# platform_designer_hps_system_hps_0_hps register map
Vendor: default_vendor.com; File version: 0.0
Registers are 32-bit, read-write, reset 0x0 unless marked. A register's access mark holds for its fields unless they carry their own. Offsets are from the block's base; [hi:lo] are bit positions; {n}, {i} and the like mark numbered series; 'fields as' and 'values as' point back to an identical list.

## usb0 (part 3 of 4) — Registers in the USB OTG Controller Module. Only the Core Global, Power and Clock Gating, Data FIFO Access, and Host Port registers can be accessedin both Host and Device modes. When the USB OTG Controller is operating in one mode, either Device or Host, the application must not access registers from the other mode. If an illegal access occurs, a Mode Mismatch interrupt is generated and reflected in the Core Interrupt register (GINTSTS.ModeMis). When the core switches from one mode to another, the registers in the new mode must be reprogrammed as they would be after a power-on reset. The register address map is fixed and does not depend on the module configuration (for example, how many endpoints are implemented). Host and Device mode registers occupy different addresses.
Base 0xFFB00000
Same registers: usb1 0xFFB40000
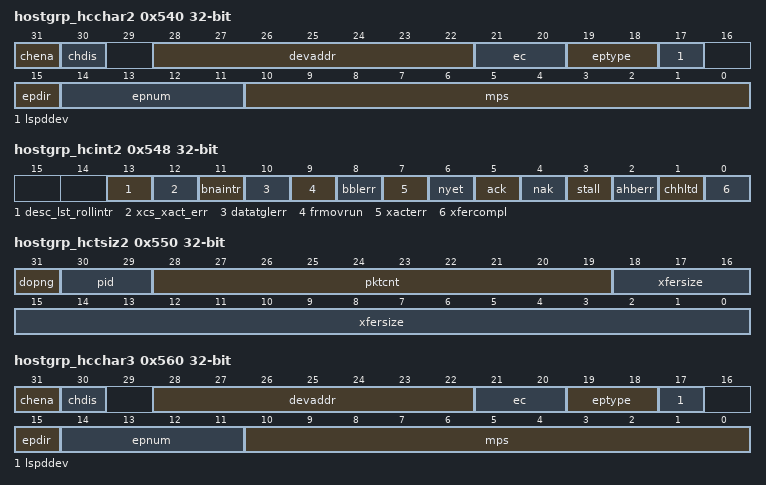
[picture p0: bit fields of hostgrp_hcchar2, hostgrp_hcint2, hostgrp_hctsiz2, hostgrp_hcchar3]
0x540 hostgrp_hcchar2 — Host Channel 2 Characteristics Register
  [31] chena ro — When Scatter/Gather mode is disabled This field is set by the application and cleared by the OTG host. 0: Channel disabled 1: Channel enabled When Scatter/Gather mode is enabled.
    0=inactive; 1=active
  [30] chdis ro — The application sets this bit to stop transmitting/receiving data on a channel, even before the transfer for that channel is complete. The application must wait for the Channel Disabled interrupt before treating the channel as disabled.
    0=inactive; 1=active
  [28:22] devaddr — This field selects the specific device serving as the data source or sink.
  [21:20] ec — When the Split Enable bit of the Host Channel-n Split Control register (HCSPLTn.SpltEna) is reset (0), this field indicates to the host the number of transactions that must be executed per microframe for this periodic endpoint. for non periodic transfers, this field is used only in DMA mode, and specifies the number packets to be fetched for this channel before the internal DMA engine changes arbitration. When HCSPLTn.SpltEna is Set (1), this field indicates the number of immediate retries to be performed for a periodic split transactions on transaction errors. This field must be set to at least 1.
    1=transone; 2=transtwo; 3=transthree
  [19:18] eptype — Indicates the transfer type selected.
    0=ctrl; 1=isoc; 2=bulk; 3=interr
  [17] lspddev — This field is set by the application to indicate that this channel is communicating to a low-speed device. The application must program this bit when a low speed device is connected to the host through an FS HUB. The HS OTG Host core uses this field to drive the XCVR_SELECT signal to 0x3 while communicating to the LS Device through the FS hub. In a peer to peer setup, the HS OTG Host core ignores this bit even if it is set by the application software
    0=disabled; 1=enabled
  [15] epdir — Indicates whether the transaction is IN or OUT.
    0=out; 1=in
  [14:11] epnum — Indicates the endpoint number on the device serving as the data source or sink.
    {v}=endpt{v} (v=0..15)
  [10:0] mps — Indicates the maximum packet size of the associated endpoint.
0x548 hostgrp_hcint2 ro — This register indicates the status of a channel with respect to USB- and AHB-related events. The application must read this register when the Host Channels Interrupt bit of the Core Interrupt register (GINTSTS.HChInt) is set. Before the application can read this register, it must first read the Host All Channels Interrupt (HAINT) register to get the exact channel number for the Host Channel-n Interrupt register. The application must clear the appropriate bit in this register to clear the corresponding bits in the HAINT and GINTSTS registers.
  [13] desc_lst_rollintr — Descriptor rollover interrupt (DESC_LST_ROLLIntr)This bit is valid only when Scatter/Gather DMA mode is enabled. The core sets this bit when the corresponding channel's descriptor list rolls over. for non Scatter/Gather DMA mode, this bit is reserved.
    0=inactive; 1=active
  [12] xcs_xact_err — This bit is valid only when Scatter/Gather DMA mode is enabled. The core sets this bit when 3 consecutive transaction errors occurred on the USB bus. XCS_XACT_ERR will not be generated for Isochronous channels.for non Scatter/Gather DMA mode, this bit is reserved.
    0=inactive; 1=acvtive
  [11] bnaintr — This bit is valid only when Scatter/Gather DMA mode is enabled. The core generates this interrupt when the descriptor accessed is not ready for the Core to process. BNA will not be generated for Isochronous channels. for non Scatter/Gather DMA mode, this bit is reserved.
    0=inactive; 1=active
  [10] datatglerr — This bit can be set only by the core and the application should write 1 to clear it. In Scatter/Gather DMA mode, the interrupt due to this bit is masked in the core.
    0=inactive; 1=active
  [9] frmovrun — In Scatter/Gather DMA mode, the interrupt due to this bit is masked in the core. This bit can be set only by the core and the application should write 1 to clear it.
    0=inactive; 1=active
  [8] bblerr — In Scatter/Gather DMA mode, the interrupt due to this bit is masked in the core..This bit can be set only by the core and the application should write 1 to clear it.
    0=inactive; 1=active
  [7] xacterr — Indicates one of the following errors occurred on the USB.-CRC check failure -Timeout -Bit stuff error -False EOP In Scatter/Gather DMA mode, the interrupt due to this bit is masked in the core. This bit can be set only by the core and the application should write 1 to clear it.
    0=inactive; 1=active
  [6] nyet — In Scatter/Gather DMA mode, the interrupt due to this bit is masked in the core.This bit can be set only by the core and the application should write 1 to clear it.
    0=inactive; 1=active
  [5] ack — In Scatter/Gather DMA mode, the interrupt due to this bit is masked in the core. This bit can be set only by the core and the application should write 1 to clear it.
    0=inactive; 1=active
  [4] nak — In Scatter/Gather DMA mode, the interrupt due to this bit is masked in the core.This bit can be set only by the core and the application should write 1 to clear it.
    0=inactive; 1=active
  [3] stall — In Scatter/Gather DMA mode, the interrupt due to this bit is masked in the core. This bit can be set only by the core and the application should write 1 to clear it.
    0=inactive; 1=active
  [2] ahberr — This is generated only in Internal DMA mode when there is an AHB error during AHB read/write. The application can read the corresponding channel's address register to get the error address.
    0=inactive; 1=active
  [1] chhltd — In non Scatter/Gather DMA mode, it indicates the transfer completed abnormally either because of any USB transaction error or in response to disable request by the application or because of a completed transfer. In Scatter/gather DMA mode, this indicates that transfer completed due to any of the following . EOL being set in descriptor . AHB error . Excessive transaction errors . Babble . Stall
    0=inactive; 1=active
  [0] xfercompl — Transfer completed normally without any errors. This bit can be set only by the core and the application should write 1 to clear it.
    0=inactive; 1=active
0x550 hostgrp_hctsiz2 — Buffer DMA Mode.
  [31] dopng — This bit is used only for OUT transfers.Setting this field to 1 directs the host to do PING protocol. Do not Set this bit for IN transfers. If this bit is set for IN transfers it disables the channel.
    0=noping; 1=ping
  [30:29] pid — The application programs this field with the type of PID to use forthe initial transaction. The host maintains this field for the rest of the transfer.
    0=data0; 1=data2; 2=data1; 3=mdata
  [28:19] pktcnt — This field is programmed by the application with the expected number of packets to be transmitted (OUT) or received (IN). The host decrements this count on every successful transmission or reception of an OUT/IN packet. Once this count reaches zero, the application is interrupted to indicate normal completion. The width of this counter is specified as 10 bits.
  [18:0] xfersize — for an OUT, this field is the number of data bytes the host sends during the transfer. for an IN, this field is the buffer size that the application has Reserved for the transfer. The application is expected to program this field as an integer multiple of the maximum packet size for IN transactions (periodic and non-periodic).The width of this counter is specified as 19 bits.
0x560 hostgrp_hcchar3 — Channel_number: 3.
  [31] chena ro — When Scatter/Gather mode is disabled. This field is set by the application and cleared by the OTG host.
    0=notready; 1=ready
  [30] chdis ro — The application sets this bit to stop transmitting/receiving data on a channel, even before the transfer for that channel is complete. The application must wait for the Channel Disabled interrupt before treating the channel as disabled.
    0=inactive; 1=active
  [28:22] devaddr — This field selects the specific device serving as the data source or sink.
  [21:20] ec — When the Split Enable bit of the Host Channel-n Split Control register (HCSPLTn.SpltEna) is reset (0), this field indicates to the host the number of transactions that must be executed per microframe for this periodic endpoint. for non periodic transfers, this field is used only in DMA mode, and specifies the number packets to be fetched for this channel before the internal DMA engine changes arbitration. When HCSPLTn.SpltEna is Set (1), this field indicates the number of immediate retries to be performed for a periodic split transactions on transaction errors. This field must be Set to at least 1.
    1=transone; 2=transtwo; 3=transthree
  [19:18] eptype — Indicates the transfer type selected.
    0=ctrl; 1=isoc; 2=bulk; 3=interr
  [17] lspddev — This field is Set by the application to indicate that this channel is communicating to a low-speed device. The application must program this bit when a low speed device is connected to the host through an FS HUB. The HS OTG Host core uses this field to drive the XCVR_SELECT signal to 0x3 while communicating to the LS Device through the FS hub. In a peer to peer setup, the HS OTG Host core ignores this bit even if it is set by the application software.
    0=nonlowspeed; 1=lowspeed
  [15] epdir — Indicates whether the transaction is IN or OUT.
    0=outdir; 1=indir
  [14:11] epnum — Indicates the endpoint number on the device serving as the data source or sink.
    {v}=endpt{v} (v=0..15)
  [10:0] mps — Indicates the maximum packet size of the associated endpoint.
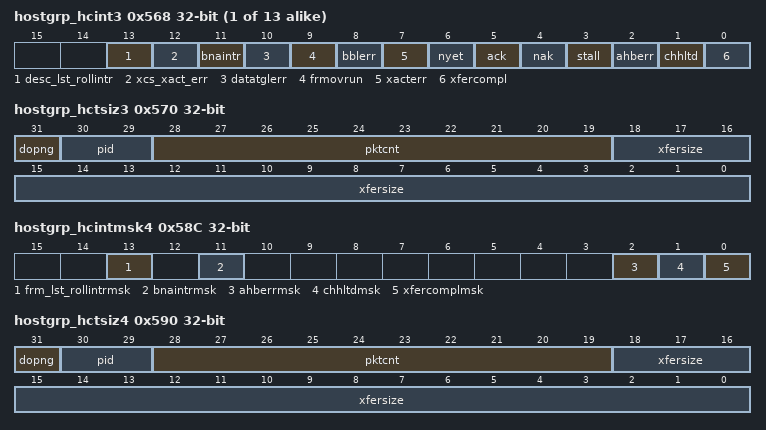
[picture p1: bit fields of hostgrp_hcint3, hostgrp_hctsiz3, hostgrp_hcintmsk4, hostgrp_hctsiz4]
{0x508+0x20*i} hostgrp_hcint{i} ro (i=3..15) — This register indicates the status of a channel with respect to USB- and AHB-related events. The application must read this register when the Host Channels Interrupt bit of the Core Interrupt register (GINTSTS.HChInt) is set. Before the application can read this register, it must first read the Host All Channels Interrupt (HAINT) register to get the exact channel number for the Host Channel-n Interrupt register. The application must clear the appropriate bit in this register to clear the corresponding bits in the HAINT and GINTSTS registers.
  [13] desc_lst_rollintr — Descriptor rollover interrupt (DESC_LST_ROLLIntr)This bit is valid only when Scatter/Gather DMA mode is enabled. The core sets this bit when the corresponding channel's descriptor list rolls over. for non Scatter/Gather DMA mode, this bit is reserved.
    0=inactive; 1=active
  [12] xcs_xact_err — This bit is valid only when Scatter/Gather DMA mode is enabled. The core sets this bit when 3 consecutive transaction errors occurred on the USB bus. XCS_XACT_ERR will not be generated for Isochronous channels.for non Scatter/Gather DMA mode, this bit is reserved.
    0=inactive; 1=acvtive
  [11] bnaintr — This bit is valid only when Scatter/Gather DMA mode is enabled. The core generates this interrupt when the descriptor accessed is not ready for the Core to process. BNA will not be generated for Isochronous channels. for non Scatter/Gather DMA mode, this bit is reserved.
    0=inactive; 1=active
  [10] datatglerr — This bit can be set only by the core and the application should write 1 to clear it. In Scatter/Gather DMA mode, the interrupt due to this bit is masked in the core.
    0=inactive; 1=active
  [9] frmovrun — In Scatter/Gather DMA mode, the interrupt due to this bit is masked in the core. This bit can be set only by the core and the application should write 1 to clear it.
    0=inactive; 1=active
  [8] bblerr — In Scatter/Gather DMA mode, the interrupt due to this bit is masked in the core..This bit can be set only by the core and the application should write 1 to clear it.
    0=inactive; 1=active
  [7] xacterr — Indicates one of the following errors occurred on the USB.-CRC check failure -Timeout -Bit stuff error -False EOP In Scatter/Gather DMA mode, the interrupt due to this bit is masked in the core. This bit can be set only by the core and the application should write 1 to clear it.
    0=inactive; 1=active
  [6] nyet — In Scatter/Gather DMA mode, the interrupt due to this bit is masked in the core.This bit can be set only by the core and the application should write 1 to clear it.
    0=inactive; 1=active
  [5] ack — In Scatter/Gather DMA mode, the interrupt due to this bit is masked in the core. This bit can be set only by the core and the application should write 1 to clear it.
    0=inactive; 1=active
  [4] nak — In Scatter/Gather DMA mode, the interrupt due to this bit is masked in the core.This bit can be set only by the core and the application should write 1 to clear it.
    0=inactive; 1=active
  [3] stall — In Scatter/Gather DMA mode, the interrupt due to this bit is masked in the core. This bit can be set only by the core and the application should write 1 to clear it.
    0=inactive; 1=active
  [2] ahberr — This is generated only in Internal DMA mode when there is an AHB error during AHB read/write. The application can read the corresponding channel's DMA address register to get the error address.
    0=inactive; 1=active
  [1] chhltd — In non Scatter/Gather DMA mode, it indicates the transfer completed abnormally either because of any USB transaction error or in response to disable request by the application or because of a completed transfer. In Scatter/gather DMA mode, this indicates that transfer completed due to any of the following . EOL being set in descriptor . AHB error . Excessive transaction errors . Babble . Stall
    0=inactive; 1=active
  [0] xfercompl — Transfer completed normally without any errors. This bit can be set only by the core and the application should write 1 to clear it.
    0=inactive; 1=active
0x570 hostgrp_hctsiz3 — Buffer DMA Mode
  fields as hostgrp_hctsiz2
0x580 hostgrp_hcchar4 — These registers are present only in case of Scatter/Gather DMA. These registers are implemented in RAM instead of flop-based implementation. Holds the current buffer address. This register is updated as and when the data transfer for the corresponding end point is in progress. This register is present only in Scatter/Gather DMA mode. Otherwise this field is reserved.
  [31:0] hcdmab4
0x58C hostgrp_hcintmsk4 — This register reflects the mask for Channel 4 interrupt status bits.
  [all] fields
    0=mask; 1=nomask
  [13] frm_lst_rollintrmsk — This bit is valid only when Scatter/Gather DMA mode is enabled.
  [11] bnaintrmsk — This bit is valid only when Scatter/Gather DMA mode is enabled.
  [2] ahberrmsk — In scatter/gather DMA mode for host, interrupts will not be generated due to the corresponding bits set in HCINTn.
  [1] chhltdmsk — Channel Halted.
  [0] xfercomplmsk — Transfer complete.
0x590 hostgrp_hctsiz4 — Buffer DMA Mode Channel 4
  fields as hostgrp_hctsiz2
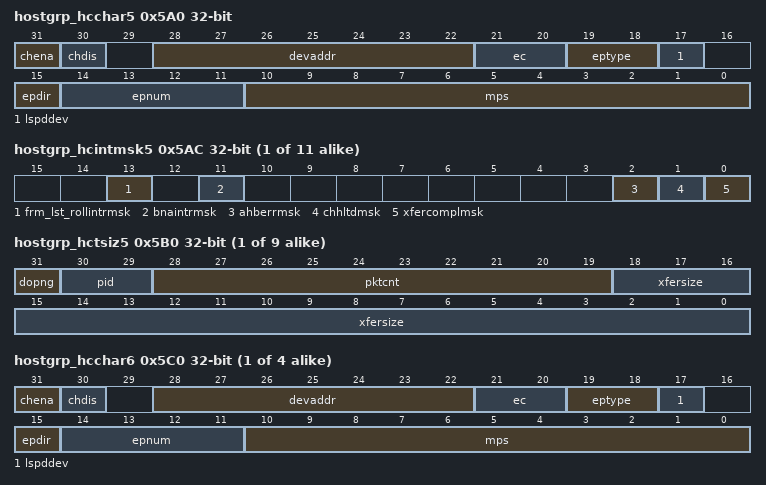
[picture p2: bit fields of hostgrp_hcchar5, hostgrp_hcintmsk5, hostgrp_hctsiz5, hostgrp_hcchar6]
0x5A0 hostgrp_hcchar5 — Channel_number: 5.
  [31] chena ro — When Scatter/Gather mode is disabled. This field is set by the application and cleared by the OTG host.
    0=notready; 1=ready
  [30] chdis ro — The application sets this bit to stop transmitting/receiving data on a channel, even before the transfer for that channel is complete. The application must wait for the Channel Disabled interrupt before treating the channel as disabled.
    0=inactive; 1=active
  [28:22] devaddr — This field selects the specific device serving as the data source or sink.
  [21:20] ec — When the Split Enable bit of the Host Channel-n Split Control register (HCSPLTn.SpltEna) is reset (0), this field indicates to the host the number of transactions that must be executed per microframe for this periodic endpoint. for non periodic transfers, this field is used only in DMA mode, and specifies the number packets to be fetched for this channel before the internal DMA engine changes arbitration. 0x0: Reserved This field yields undefined results. 0x1: transaction 0x2: 2 transactions to be issued for this endpoint permicroframe 0x3: 3 transactions to be issued for this endpoint permicroframeWhen HCSPLTn.SpltEna is Set (1), this field indicates thenumber of immediate retries to be performed for a periodic splittransactions on transaction errors. This field must be Set to atleast 1.
    1=transone; 2=transtwo; 3=transthree
  [19:18] eptype — Indicates the transfer type selected.
    0=ctrl; 1=isoc; 2=bulk; 3=interr
  [17] lspddev — This field is Set by the application to indicate that this channel is communicating to a low-speed device. The application must program this bit when a low speed device is connected to the host through an FS HUB. The HS OTG Host core uses this field to drive the XCVR_SELECT signal to 0x3 while communicating to the LS Device through the FS hub. In a peer to peer setup, the HS OTG Host core ignores this bit even if it is set by the application software.
    0=nonlowspeed; 1=lowspeed
  [15] epdir — Indicates whether the transaction is IN or OUT.
    0=outdir; 1=indir
  [14:11] epnum — Indicates the endpoint number on the device serving as the data source or sink.
    {v}=endpt{v} (v=0..15)
  [10:0] mps — Indicates the maximum packet size of the associated endpoint.
{0x50C+0x20*i} hostgrp_hcintmsk{i} (i=5..15) — This register reflects the mask for each channel status described in the previous section.
  fields as hostgrp_hcintmsk4
{0x510+0x20*i} hostgrp_hctsiz{i} (i=5..13) — Buffer DMA Mode
  fields as hostgrp_hctsiz2
{0x500+0x20*i} hostgrp_hcchar{i} (i=6..9) — Host Channel {i} Characteristics Register
  fields as hostgrp_hcchar2
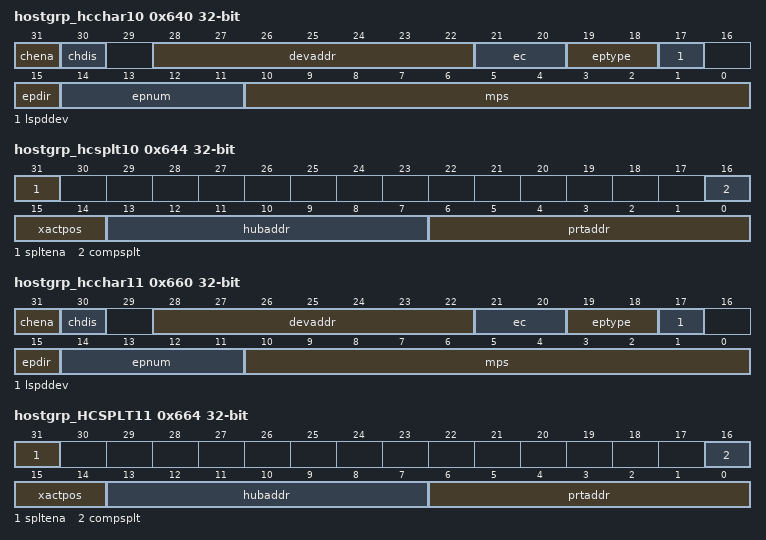
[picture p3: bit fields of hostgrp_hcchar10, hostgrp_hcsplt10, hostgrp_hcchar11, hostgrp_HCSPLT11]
0x640 hostgrp_hcchar10 — Host Channel 1 Characteristics Register
  fields as hostgrp_hcchar2
0x644 hostgrp_hcsplt10 — Channel_number 1
  [31] spltena — The application sets this field to indicate that this channel is enabled to perform split transactions.
    0=disabled; 1=enabled
  [16] compsplt — The application sets this field to request the OTG host to perform a complete split transaction.
    0=nosplit; 1=split
  [15:14] xactpos — This field is used to determine whether to send all, first, middle, or last payloads with each OUT transaction.
    0=middle; 1=end; 2=begin; 3=all
  [13:7] hubaddr — This field holds the device address of the transaction translator's hub.
  [6:0] prtaddr — This field is the port number of the recipient transactiontranslator.
0x660 hostgrp_hcchar11 — Host Channel 11 Characteristics Register
  fields as hostgrp_hcchar2
0x664 hostgrp_HCSPLT11 — Channel number 11.
  fields as hostgrp_hcsplt10
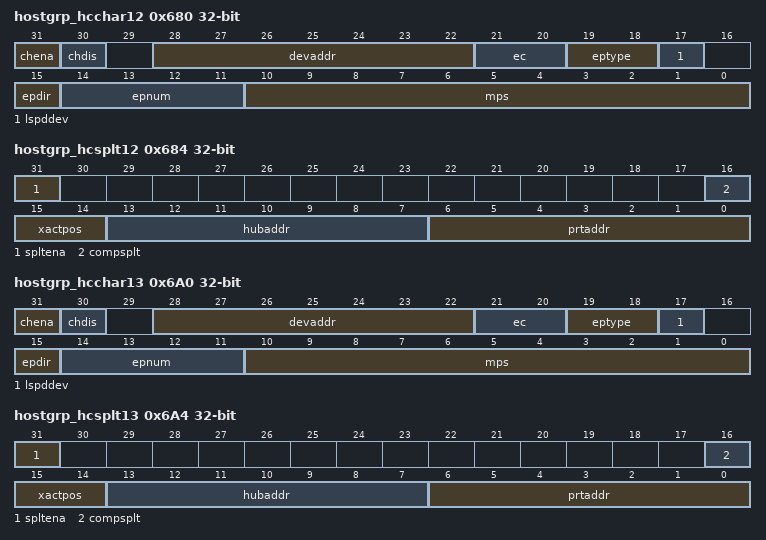
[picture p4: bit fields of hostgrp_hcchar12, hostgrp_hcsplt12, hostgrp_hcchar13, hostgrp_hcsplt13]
0x680 hostgrp_hcchar12 — Host Channel 1 Characteristics Register
  fields as hostgrp_hcchar2
0x684 hostgrp_hcsplt12 — Channel_number 1
  fields as hostgrp_hcsplt10
0x6A0 hostgrp_hcchar13 — Host Channel 13 Characteristics Register
  fields as hostgrp_hcchar2
0x6A4 hostgrp_hcsplt13 — Channel_number 13.
  fields as hostgrp_hcsplt10
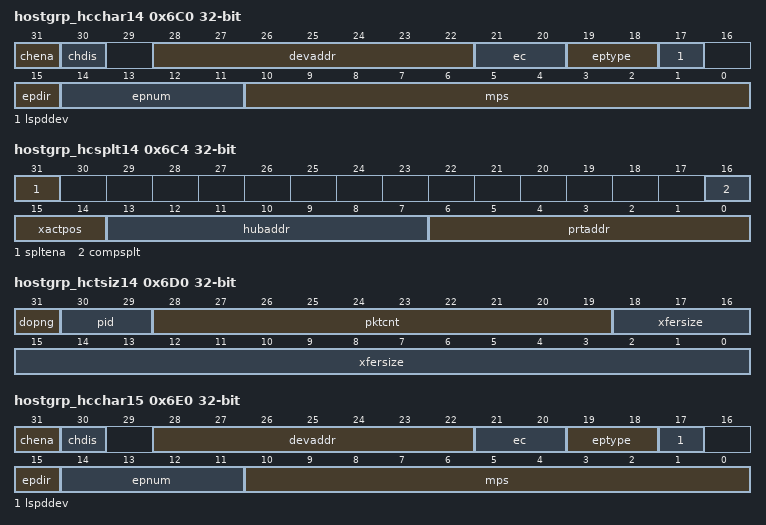
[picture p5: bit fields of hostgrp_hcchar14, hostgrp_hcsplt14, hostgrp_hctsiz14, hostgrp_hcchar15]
0x6C0 hostgrp_hcchar14 — Host Channel 1 Characteristics Register
  fields as hostgrp_hcchar2
0x6C4 hostgrp_hcsplt14 — Channel_number 14
  fields as hostgrp_hcsplt10
0x6D0 hostgrp_hctsiz14
  [31] dopng — This bit is used only for OUT transfers.Setting this field to 1 directs the host to do PING protocol. Do not Set this bit for IN transfers. If this bit is set for IN transfers it disables the channel.
    0=noping; 1=ping
  [30:29] pid — The application programs this field with the type of PID to use forthe initial transaction. The host maintains this field for the rest of the transfer.
    0=data0; 1=data2; 2=data1; 3=mdata
  [28:19] pktcnt — This field is programmed by the application with the expected number of packets to be transmitted (OUT) or received (IN). The host decrements this count on every successful transmission or reception of an OUT/IN packet. Once this count reaches zero, the application is interrupted to indicate normal completion. The width of this counter is specified as 10 bits.
  [18:0] xfersize — for an OUT, this field is the number of data bytes the host sends during the transfer. for an IN, this field is the buffer size that the application has Reserved for the transfer. The application is expected to program this field as an integer multiple of the maximum packet size for IN transactions (periodic and non-periodic). The width of this counter is specified as 19 bits.
0x6E0 hostgrp_hcchar15 — Host Channel 15 Characteristics Register
  [31] chena ro — When Scatter/Gather mode is disabled This field is set by the application and cleared by the OTG host. 0: Channel disabled 1: Channel enabled When Scatter/Gather mode is enabled.
    0=inactive; 1=active
  [30] chdis ro — The application sets this bit to stop transmitting/receiving data on a channel, even before the transfer for that channel is complete. The application must wait for the Channel Disabled interrupt before treating the channel as disabled.
    0=inactive; 1=active
  [28:22] devaddr — This field selects the specific device serving as the data source or sink.
  [21:20] ec — When the Split Enable bit of the Host Channel-n Split Control register (HCSPLTn.SpltEna) is reset (0), this field indicates to the host the number of transactions that must be executed per microframe for this periodic endpoint. for non periodic transfers, this field is used only in DMA mode, and specifies the number packets to be fetched for this channel before the internal DMA engine changes arbitration. When HCSPLTn.SpltEna is Set (1), this field indicates the number of immediate retries to be performed for a periodic split transactions on transaction errors. This field must be set to at least 1.
    1=transone; 2=transtwo; 3=transthree
  [19:18] eptype — Indicates the transfer type selected.
    0=ctrl; 1=isoc; 2=bulk; 3=interr
  [17] lspddev — This field is set by the application to indicate that this channel is communicating to a low-speed device. The application must program this bit when a low speed device is connected to the host through an FS HUB. The HS OTG Host core uses this field to drive the XCVR_SELECT signal to 2'b11 while communicating to the LS Device through the FS hub. In a peer to peer setup, the HS OTG Host core ignores this bit even if it is set by the application software
    0=disabled; 1=enabled
  [15] epdir — Indicates whether the transaction is IN or OUT.
    0=out; 1=in
  [14:11] epnum — Indicates the endpoint number on the device serving as the data source or sink.
    {v}=endpt{v} (v=0..15)
  [10:0] mps — Indicates the maximum packet size of the associated endpoint.
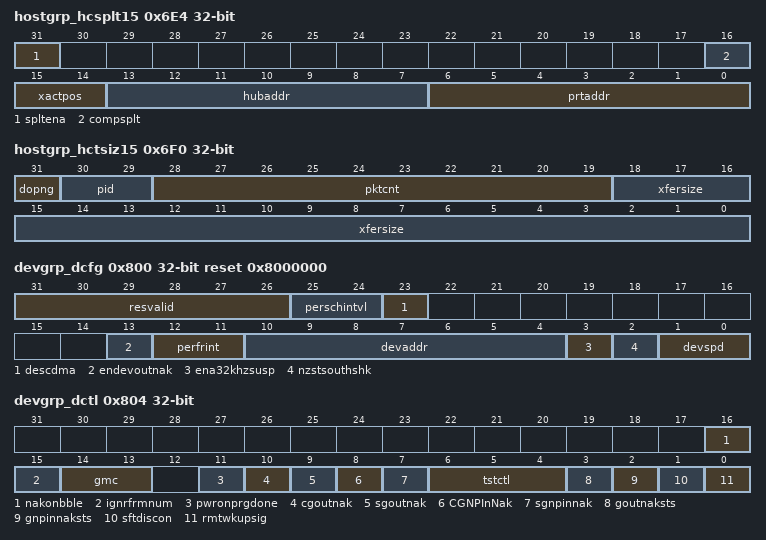
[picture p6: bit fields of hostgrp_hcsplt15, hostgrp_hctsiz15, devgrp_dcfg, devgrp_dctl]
0x6E4 hostgrp_hcsplt15 — Channel_number 15.
  fields as hostgrp_hcsplt10
0x6F0 hostgrp_hctsiz15
  fields as hostgrp_hctsiz2
0x800 devgrp_dcfg reset 0x8000000 — This register configures the core in Device mode after power-on or after certain control commands or enumeration. Do not make changes to this register after initial programming.
  [31:26] resvalid — This field is effective only when DCFG.Ena32KHzSusp is set. It will control the resume period when the core resumes from suspend. The core counts for ResValid number of clock cycles to detect a valid resume when this is set
  [25:24] perschintvl — PerSchIntvl must be programmed only for Scatter/Gather DMAmode. Description: This field specifies the amount of time the Internal DMA engine must allocate for fetching periodic IN endpoint data. Based on the number of periodic endpoints, this value must be specified as 25,50 or 75% of (micro)frame. When any periodic endpoints are active, the internal DMA engine allocates the specified amount of time in fetching periodic IN endpoint data . When no periodic endpoints are active, Then the internal DMA engine services non-periodic endpoints, ignoring this field. After the specified time within a (micro)frame, the DMA switches to fetching for non-periodic endpoints. 2'b00: 25% of (micro)frame. 2'b01: 50% of (micro)frame. 2'b10: 75% of (micro)frame. 2'b11: Reserved.Reset: 2'b00Access: read-write
    0=mf25; 1=mf50; 2=mf75
  [23] descdma — When the Scatter/Gather DMA option selected during configuration of the RTL, the application can Set this bit during initialization to enable the Scatter/Gather DMA operation. This bit must be modified only once after a reset.The following combinations are available for programming: GAHBCFG.DMAEn=0,DCFG.DescDMA=0 => Slave mode GAHBCFG.DMAEn=0,DCFG.DescDMA=1 => Invalid GAHBCFG.DMAEn=1,DCFG.DescDMA=0 => Buffered DMA mode GAHBCFG.DMAEn=1,DCFG.DescDMA=1 => Scatter/Gather DMA mode
    0=disabled; 1=enabled
  [13] endevoutnak — This bit enables setting NAK for Bulk OUT endpoints after the transfer is completed for Device mode Descriptor DMA It is one time programmable after reset like any other DCFG register bits.
    0=disabled; 1=enabled
  [12:11] perfrint — Indicates the time within a (micro)frame at which the application must be notified using the End Of Periodic Frame Interrupt. This can be used to determine If all the isochronous traffic for that (micro)frame is complete. 0x0: 80% of the (micro)frame interval 0x1: 85% 0x2: 90% 0x3: 95%
    0=eopf80; 1=eopf85; 2=eopf90; 3=eopf95
  [10:4] devaddr — The application must program this field after every SetAddress control command.
  [3] ena32khzsusp — When the USB 1.1 Full-Speed Serial Transceiver Interface is chosen and this bit is set, the core expects the 48-MHz PHY clock to be switched to 32 KHz during a suspend. This bit can only be set if USB 1.1 Full-Speed Serial Transceiver Interface has been selected. If USB 1.1 Full-Speed Serial Transceiver Interface has not been selected, this bit must be zero.
    0=disabled; 1=enabled
  [2] nzstsouthshk — The application can use this field to select the handshake the core sends on receiving a nonzero-length data packet during the OUT transaction of a control transfer's Status stage. 1: Send a STALL handshake on a nonzero-length statusOUT transaction and do not send the received OUT packet tothe application. 0: Send the received OUT packet to the application (zerolengthor nonzero-length) and send a handshake based onthe NAK and STALL bits for the endpoint in the DeviceEndpoint Control register.
    0=sendout; 1=sendstall
  [1:0] devspd — Indicates the speed at which the application requires the core to enumerate, or the maximum speed the application can support. However, the actual bus speed is determined only after the chirp sequence is completed, and is based on the speed of the USB host to which the core is connected.
    0=usbhs20; 1=usbfs20; 2=usbls116; 3=usbls1148
0x804 devgrp_dctl
  [16] nakonbble — Set NAK automatically on babble (NakOnBble). The core sets NAK automatically for the endpoint on which babble is received.
    0=disabled; 1=enabled
  [15] ignrfrmnum — Do NOT program IgnrFrmNum bit to 1'b1 when the core is operating in threshold mode. When Scatter/Gather DMA mode is enabled this feature is not applicable to High Speed, High bandwidth transfers. When this bit is enabled, there must be only one packet per descriptor. In Scatter/Gather DMA mode, if this bit is enabled, the packets are not flushed when a ISOC IN token is received for an elapsed frame. When Scatter/Gather DMA mode is disabled, this field is used by the application to enable periodic transfer interrupt. The application can program periodic endpoint transfers for multiple (micro)frames. 0: periodic transfer interrupt feature is disabled, application needs to program transfers for periodic endpoints every (micro)frame 1: periodic transfer interrupt feature is enabled, application can program transfers for multiple (micro)frames for periodic endpoints. In non Scatter/Gather DMA mode the application will receive transfer complete interrupt after transfers for multiple (micro)frames are completed.
    0=disabled; 1=enabled
  [14:13] gmc — GMC must be programmed only once after initialization.Applicable only for Scatter/Gather DMA mode. This indicates the number of packets to be serviced for that end point before moving to the next end point. It is only for non-periodic end points. When Scatter/Gather DMA mode is disabled, this field isreserved. and reads 0.
    0=notvalid; 1=onepacket; 2=twopacket; 3=threepacket
  [11] pwronprgdone — The application uses this bit to indicate that registerprogramming is completed after a wake-up from Power Downmode.
    0=notdone; 1=done
  [10] cgoutnak wo — A write to this field clears the Global OUT NAK.
    0=disabled; 1=enabled
  [9] sgoutnak wo — A write to this field sets the Global OUT NAK.The application uses this bit to send a NAK handshake on all OUT endpoints. The application must Set the this bit only after making sure that the Global OUT NAK Effective bit in the Core Interrupt Register GINTSTS.GOUTNakEff) is cleared.
    0=disabled; 1=enabled
  [8] CGNPInNak wo — A write to this field clears the Global Non-periodic IN NAK.
    0=disable; 1=enable
  [7] sgnpinnak wo — A write to this field sets the Global Non-periodic IN NAK. The application uses this bit to send a NAK handshake on all nonperiodic IN endpoints. The core can also Set this bit when a timeout condition is detected on a non-periodic endpoint in shared FIFO operation. The application must Set this bit only after making sure that the Global IN NAK Effective bit in the Core Interrupt Register (GINTSTS.GINNakEff) is cleared
    0=disabled; 1=enabled
  [6:4] tstctl — Others: Reserved.
    0=disabled; 1=testj; 2=testk; 3=testsn; 4=testpm; 5=testfe
  [3] goutnaksts ro — Reports NAK status. All isochronous OUT packets aredropped.
    0=inactive; 1=active
  [2] gnpinnaksts ro — Defines IN NAK conditions.
    0=inactive; 1=active
  [1] sftdiscon — The application uses this bit to signal the otg core to do a soft disconnect. As long as this bit is Set, the host does not see that the device is connected, and the device does not receive signals on the USB. The core stays in the disconnected state until the application clears this bit. There is a minimum duration for which the core must keep this bit set. When this bit is cleared after a soft disconnect, the core drives the phy_opmode_o signal on the ULPI, which generates a device connect event to the USB host. When the device is reconnected, the USB host restarts device enumeration.;
    0=nodisconnect; 1=disconnect
  [0] rmtwkupsig — When the application sets this bit, the core initiates remote signaling to wake up the USB host. The application must Set this bit to instruct the core to exit the Suspend state. As specified in the USB 2.0 specification, the application must clear this bit 115 ms after setting it. Remote Wakeup Signaling (RmtWkUpSig) When LPM is enabled, In L1 state the behavior of this bit is as follows: When the application sets this bit, the core initiates L1 remote signaling to wake up the USB host. The application must set this bit to instruct the core to exit the Sleep state. As specified in the LPM specification, the hardware will automatically clear this bit after a time of 50us (TL1DevDrvResume) after set by application. Application should not set this bit when GLPMCFG bRemoteWake from the previous LPM transaction was zero.
    0=noexit; 1=exit
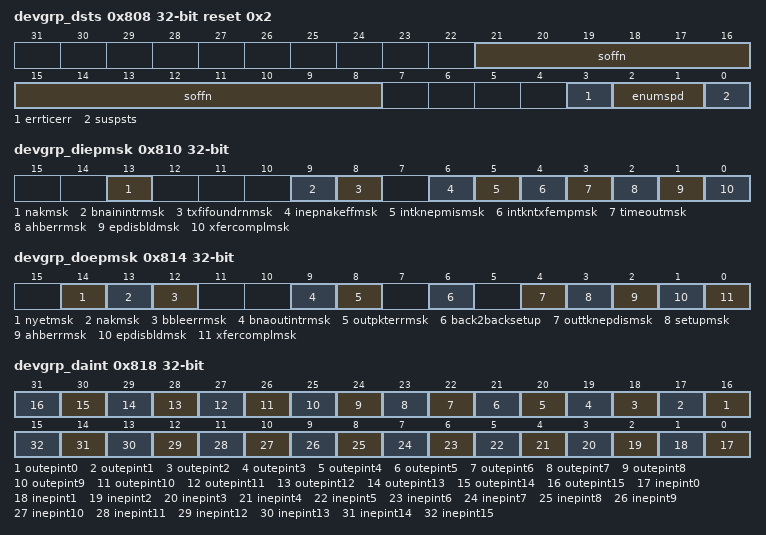
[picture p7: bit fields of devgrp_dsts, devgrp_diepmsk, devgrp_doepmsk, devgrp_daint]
0x808 devgrp_dsts ro reset 0x2 — This register indicates the status of the core with respect to USB-related events. It must be read on interrupts from Device All Interrupts (DAINT) register.
  [21:8] soffn — When the core is operating at high speed, this field contains a microframe number. When the core is operating at full or low speed, this field contains a Frame number.
  [3] errticerr — The core sets this bit to report any erratic errors (phy_rxvalid_i/phy_rxvldh_i or phy_rxactive_i is asserted for at least 2 ms, due to PHY error) seen on the UTMI+ . Due to erratic errors, the otg core goes into Suspended state and an interrupt is generated to the application with Early Suspend bit of the Core Interrupt register (GINTSTS.ErlySusp). If the early suspend is asserted due to an erratic error, the application can only perform a soft disconnect recover.
    0=inactive; 1=active
  [2:1] enumspd — Indicates the speed at which the otg core has come up after speed detection through a chirp sequence.
    0=hs3060; 1=fs3060; 2=ls6; 3=fs48
  [0] suspsts — In Device mode, this bit is Set as long as a Suspend condition is detected on the USB. The core enters the Suspended state when there is no activity on the phy_line_state_i signal for an extended period of time. The core comes out of the suspend: -When there is any activity on the phy_line_state_i signal -When the application writes to the Remote Wakeup Signaling bit in the Device Control register (DCTL.RmtWkUpSig).
    0=inactive; 1=active
0x810 devgrp_diepmsk — This register works with each of the Device IN Endpoint Interrupt (DIEPINTn) registers for all endpoints to generate an interrupt per IN endpoint. The IN endpoint interrupt for a specific status in the DIEPINTn register can be masked by writing to the corresponding bit in this register. Status bits are masked by default.
  [all] fields
    0=mask; 1=nomask
  [13] nakmsk
  [9] bnainintrmsk
  [8] txfifoundrnmsk
  [6] inepnakeffmsk
  [5] intknepmismsk
  [4] intkntxfempmsk
  [3] timeoutmsk — Non-isochronous endpoints
  [2] ahberrmsk
  [1] epdisbldmsk
  [0] xfercomplmsk
0x814 devgrp_doepmsk — This register works with each of the Device OUT Endpoint Interrupt (DOEPINTn) registers for all endpoints to generate an interrupt per OUT endpoint. The OUT endpoint interrupt for a specific status in the DOEPINTn register can be masked by writing into the corresponding bit in this register. Status bits are masked by default
  [all] fields
    0=mask; 1=nomask
  [14] nyetmsk
  [13] nakmsk
  [12] bbleerrmsk
  [9] bnaoutintrmsk
  [8] outpkterrmsk
  [6] back2backsetup — Applies to control OUT endpoints only.
  [4] outtknepdismsk — Applies to control OUT endpoints only.
  [3] setupmsk — Applies to control endpoints only.
  [2] ahberrmsk
  [1] epdisbldmsk
  [0] xfercomplmsk
0x818 devgrp_daint ro — When a significant event occurs on an endpoint, a Device All Endpoints Interrupt register interrupts the application using the Device OUT Endpoints Interrupt bit or Device IN Endpoints Interrupt bit of the Core Interrupt register (GINTSTS.OEPInt or GINTSTS.IEPInt, respectively). This is shown in Figure 5-2. There is one interrupt bit per endpoint, up to a maximum of 16 bits for OUT endpoints and 16 bits for IN endpoints. for a bidirectional endpoint, the corresponding IN and OUT interrupt bits are used. Bits in this register are set and cleared when the application sets and clears bits in the corresponding Device Endpoint-n Interrupt register (DIEPINTn/DOEPINTn).
  [all] fields
    0=inactive; 1=active
  [n+16] outepint{n} (n=0..15)
  [n] inepint{n} (n=0..15)
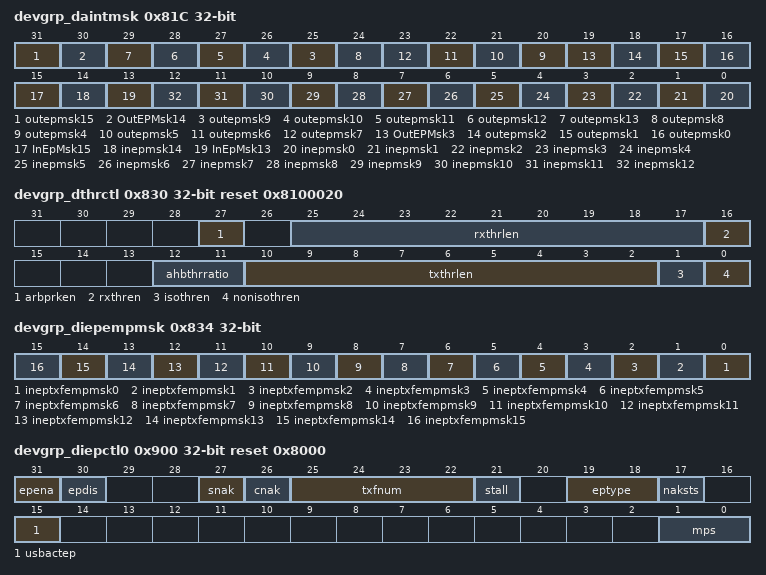
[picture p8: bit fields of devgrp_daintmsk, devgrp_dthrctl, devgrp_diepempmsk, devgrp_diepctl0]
0x81C devgrp_daintmsk — The Device Endpoint Interrupt Mask register works with the Device Endpoint Interrupt register to interrupt the application when an event occurs on a device endpoint. However, the Device All Endpoints Interrupt (DAINT) register bit corresponding to that interrupt is still set.
  [31] outepmsk15
    1=nomask; 0=mask
  [30] OutEPMsk14
    1=nomask; 0=mask
  [n+16] outepmsk{n} (n=9..13)
    1=nomask; 0=mask
  [24] outepmsk8 — OUT Endpoint 8 Interrupt mask Bit
    1=nomask; 0=mask
  [n+16] outepmsk{n} (n=4..7)
    1=nomask; 0=mask
  [19] OutEPMsk3
    1=nomask; 0=mask
  [18] outepmsk2
    1=nomask; 0=mask
  [17] outepmsk1
    1=nomask; 0=mask
  [16] outepmsk0
    1=nomask; 0=mask
  [15] InEpMsk15 — IN Endpoint 15 Interrupt mask Bit
    0=inactive; 1=active
  [14] inepmsk14
    1=nomask; 0=mask
  [13] InEpMsk13
    1=nomask; 0=mask
  [n] inepmsk{n} (n=0..12)
    1=nomask; 0=mask
0x828 devgrp_dvbusdis reset 0x17D7 — This register specifies the VBUS discharge time after VBUS pulsing during SRP.
  [15:0] dvbusdis — This value equals: VBUS discharge time in PHY clocks/1,024 The value you use depends whether the PHY is operating at 30 MHz (16-bit data width) or 60 MHz (8-bit data width). Depending on your VBUS load, this value can need adjustment.
0x82C devgrp_dvbuspulse reset 0x5B8 — This register specifies the VBUS pulsing time during SRP.
  [11:0] dvbuspulse — Specifies the VBUS pulsing time during SRP. This value equals: VBUS pulsing time in PHY clocks/1,024 The value you use depends whether the PHY is operating at 30MHz (16-bit data width) or 60 MHz (8-bit data width).
0x830 devgrp_dthrctl reset 0x8100020 — Thresholding is not supported in Slave mode and so this register must not be programmed in Slave mode. for threshold support, the AHB must be run at 60 MHz or higher.
  [27] arbprken — This bit controls internal DMA arbiter parking for IN endpoints. When thresholding is enabled and this bit is Set to one, Then the arbiter parks on the IN endpoint for which there is a token received on the USB. This is done to avoid getting into underrun conditions. By Default the parking is enabled.
    0=disabled; 1=enabled
  [25:17] rxthrlen — This field specifies Receive thresholding size in DWORDS.This field also specifies the amount of data received on the USB before the core can start transmitting on the AHB. The threshold length has to be at least eight DWORDS. The recommended value for ThrLen is to be the same as the programmed AHB Burst Length (GAHBCFG.HBstLen).
  [16] rxthren — When this bit is Set, the core enables thresholding in the receive direction.
    0=disabled; 1=enabled
  [12:11] ahbthrratio — These bits define the ratio between the AHB threshold and the MAC threshold for the transmit path only. The AHB threshold always remains less than or equal to the USB threshold, because this does not increase overhead. Both the AHB and the MAC threshold must be DWORD-aligned. The application needs to program TxThrLen and the AHBThrRatio to make the AHB Threshold value DWORD aligned. If the AHB threshold value is not DWORD aligned, the core might not behave correctly. When programming the TxThrLen and AHBThrRatio, the application must ensure that the minimum AHB threshold value does not go below 8 DWORDS to meet the USB turnaround time requirements.
    0=threszero; 1=thresone; 2=threstwo; 3=thresthree
  [10:2] txthrlen — This field specifies Transmit thresholding size in DWORDS. This also forms the MAC threshold and specifies the amount of data in bytes to be in the corresponding endpoint transmit FIFO, before the core can start transmit on the USB. The threshold length has to be at least eight DWORDS when the value of AHBThrRatio is 0. In case the AHBThrRatio is non zero the application needs to ensure that the AHB Threshold value does not go below the recommended eight DWORD. This field controls both isochronous and non-isochronous IN endpoint thresholds. The recommended value for ThrLen is to be the same as the programmed AHB Burst Length (GAHBCFG.HBstLen).
  [1] isothren — When this bit is Set, the core enables thresholding for isochronous IN endpoints.
    0=disabled; 1=enabled
  [0] nonisothren — When this bit is Set, the core enables thresholding for Non Isochronous IN endpoints.
    0=disabled; 1=enabled
0x834 devgrp_diepempmsk — This register is used to control the IN endpoint FIFO empty interrupt generation (DIEPINTn.TxfEmp).
  [all] fields
    0=mask; 1=nomask
  [n] ineptxfempmsk{n} (n=0..15) — This bit acts as mask bits for DIEPINT{n}.
0x900 devgrp_diepctl0 reset 0x8000 — This register covers Device Control IN Endpoint 0.
  [31] epena ro — When Scatter/Gather DMA mode is enabled, for IN endpoints this bit indicates that the descriptor structure and data buffer with data ready to transmit is setup. When Scatter/Gather DMA mode is disabled such as in bufferpointer based DMA mode this bit indicates that data is ready to be transmitted on the endpoint. The core clears this bit before setting the following interrupts on this endpoint: -Endpoint Disabled -Transfer Completed
    0=inactive; 1=active
  [30] epdis ro — The application sets this bit to stop transmitting data on an endpoint, even before the transfer for that endpoint is complete. The application must wait for the Endpoint Disabled interrupt before treating the endpoint as disabled. The core clears this bit before setting the Endpoint Disabled Interrupt. The application must Set this bit only If Endpoint Enable is already Set for this endpoint.
    0=inactive; 1=active
  [27] snak wo — A write to this bit sets the NAK bit for the endpoint. Using this bit, the application can control the transmission of NAK handshakes on an endpoint. The core can also Set this bit for an endpoint after a SETUP packet is received on that endpoint.
    0=noset; 1=set
  [26] cnak wo — A write to this bit clears the NAK bit for the endpoint.
    0=noclear; 1=clear
  [25:22] txfnum — for Shared FIFO operation, this value is always Set to 0, indicating that control IN endpoint 0 data is always written in the Non-Periodic Transmit FIFO. for Dedicated FIFO operation, this value is Set to the FIFO number that is assigned to IN Endpoint 0.
  [21] stall ro — The application can only Set this bit, and the core clears it, when a SETUP token is received for this endpoint. If a NAK bit, Global Nonperiodic IN NAK, or Global OUT NAK is Set along with this bit, the STALL bit takes priority.
    0=inactive; 1=active
  [19:18] eptype ro — Hardcoded to 00 for control.
    0=active
  [17] naksts ro — When this bit is Set, either by the application or core, the core stops transmitting data, even If there is data available in the TxFIFO. Irrespective of this bit's setting, the core always responds to SETUP data packets with an ACK handshake.
    0=inactive; 1=active
  [15] usbactep ro — This bit is always SET to 1, indicating that control endpoint 0 is always active in all configurations and interfaces.
    1=active0
  [1:0] mps — Applies to IN and OUT endpoints.The application must program this field with the maximum packet size for the current logical endpoint.
    0=bytes64; 1=bytes32; 2=bytes16; 3=bytes8
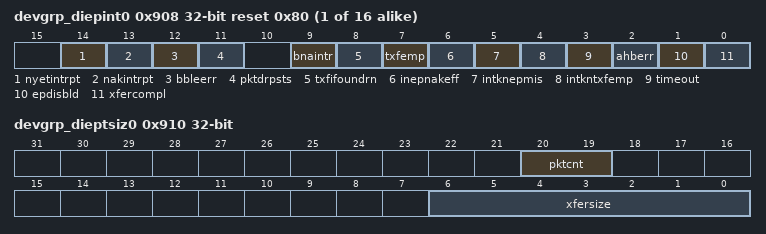
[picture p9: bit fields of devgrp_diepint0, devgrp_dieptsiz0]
{0x908+0x20*i} devgrp_diepint{i} ro reset 0x80 (i=0..15) — This register indicates the status of an endpoint with respect to USB- and AHB-related events. The application must read this register when the OUT Endpoints Interrupt bit or IN Endpoints Interrupt bit of the Core Interrupt register (GINTSTS.OEPInt or GINTSTS.IEPInt, respectively) is set. Before the application can read this register, it must first read the Device All Endpoints Interrupt (DAINT) register to get the exact endpoint number for the Device Endpoint-n Interrupt register. The application must clear the appropriate bit in this register to clear the corresponding bits in the DAINT and GINTSTS registers.
  [all] fields
    0=inactive; 1=active
  [14] nyetintrpt — The core generates this interrupt when a NYET response is transmitted for a non isochronous OUT endpoint.
  [13] nakintrpt — The core generates this interrupt when a NAK is transmitted or received by the device. In case of isochronous IN endpoints the interrupt gets generated when a zero length packet is transmitted due to un-availability of data in the TXFifo.
  [12] bbleerr — The core generates this interrupt when babble is received for the endpoint.
  [11] pktdrpsts — This bit indicates to the application that an ISOC OUT packet has been dropped. This bit does not have an associated mask bit and does not generate an interrupt.
  [9] bnaintr — This bit is valid only when Scatter/Gather DMA mode is enabled. The core generates this interrupt when the descriptor accessed is not ready for the Core to process, such as Host busy or DMA done
  [8] txfifoundrn — Applies to IN endpoints Only. The core generates this interrupt when it detects a transmit FIFO underrun condition for this endpoint.
  [7] txfemp — This bit is valid only for IN Endpoints This interrupt is asserted when the TxFIFO for this endpoint is either half or completely empty. The half or completely empty status is determined by the TxFIFO Empty Level bit in the Core AHB Configuration register (GAHBCFG.NPTxFEmpLvl)).
  [6] inepnakeff — Applies to periodic IN endpoints only. This bit can be cleared when the application clears the IN endpoint NAK by writing to DIEPCTLn.CNAK. This interrupt indicates that the core has sampled the NAK bit Set (either by the application or by the core). The interrupt indicates that the IN endpoint NAK bit Set by the application has taken effect in the core.This interrupt does not guarantee that a NAK handshake is sent on the USB. A STALL bit takes priority over a NAK bit.
  [5] intknepmis — Applies to non-periodic IN endpoints only. Indicates that the data in the top of the non-periodic TxFIFO belongs to an endpoint other than the one for which the IN token was received. This interrupt is asserted on the endpoint for which the IN token was received.
  [4] intkntxfemp — Applies to non-periodic IN endpoints only. Indicates that an IN token was received when the associated TxFIFO (periodic/non-periodic) was empty. This interrupt is asserted on the endpoint for which the IN token was received.
  [3] timeout — In shared TX FIFO mode, applies to non-isochronous IN endpoints only. In dedicated FIFO mode, applies only to Control IN endpoints. In Scatter/Gather DMA mode, the TimeOUT interrupt is notasserted. Indicates that the core has detected a timeout condition on the USB for the last IN token on this endpoint.
  [2] ahberr — Applies to IN and OUT endpoints.This is generated only in Internal DMA mode when there is an AHB error during an AHB read/write. The application can read the corresponding endpoint DMA address register to get the error address.
  [1] epdisbld — Applies to IN and OUT endpoints. This bit indicates that the endpoint is disabled per the application's request.
  [0] xfercompl — Applies to IN and OUT endpoints. When Scatter/Gather DMA mode is enabled - for IN endpoint this field indicates that the requested data from the descriptor is moved from external system memory to internal FIFO. - for OUT endpoint this field indicates that the requested data from the internal FIFO is moved to external system memory. This interrupt is generated only when the corresponding endpoint descriptor is closed, and the IOC bit for the corresponding descriptor is Set. When Scatter/Gather DMA mode is disabled, this field indicates that the programmed transfer is complete on the AHB as well as on the USB, for this endpoint.
0x910 devgrp_dieptsiz0 — The application must modify this register before enabling endpoint 0. Once endpoint 0 is enabled using Endpoint Enable bit of the Device Control Endpoint 0 Control registers (DIEPCTL0.EPEna/DOEPCTL0.EPEna), the core modifies this register. The application can only read this register once the core has cleared the Endpoint Enable bit. Nonzero endpoints use the registers for endpoints 1 to 15. When Scatter/Gather DMA mode is enabled, this register must not be programmed by the application. If the application reads this register when Scatter/Gather DMA mode is enabled, the core returns all zeros.
  [20:19] pktcnt — Indicates the total number of USB packets that constitute the Transfer Size amount of data for endpoint 0. This field is decremented every time a packet (maximum size or short packet) is read from the TxFIFO.
  [6:0] xfersize — Indicates the transfer size in bytes for endpoint 0. The core interrupts the application only after it has exhausted the transfer size amount of data. The transfer size can be Set to the maximum packet size of the endpoint, to be interrupted at the end of each packet. The core decrements this field every time a packet from the external memory is written to the TxFIFO.
{0x914+0x20*i} devgrp_diepdma{i} reset not defined (i=0..15) — DMA Addressing.
  [31:0] diepdma{i} — Holds the start address of the external memory for storing or fetching endpoint data. for control endpoints, this field stores control OUT data packets as well as SETUP transaction data packets. When more than three SETUP packets are received back-to-back, the SETUP data packet in the memory is overwritten. This register is incremented on every AHB transaction. The application can give only a DWORD-aligned address. When Scatter/Gather DMA mode is not enabled, the application programs the start address value in this field. When Scatter/Gather DMA mode is enabled, this field indicates the base pointer for the descriptor list.
